# CCG2 register map
File version: 1.0
CPU: CM0 r1p0, little endian, no MPU, no FPU, 2 interrupt priority bits
Registers are 32-bit, read-write, reset 0x0 unless marked. A register's access mark holds for its fields unless they carry their own. Offsets are from the block's base; [hi:lo] are bit positions; {n}, {i} and the like mark numbered series; 'fields as' and 'values as' point back to an identical list.

## USBPD (part 2 of 2)
Base 0x40080000
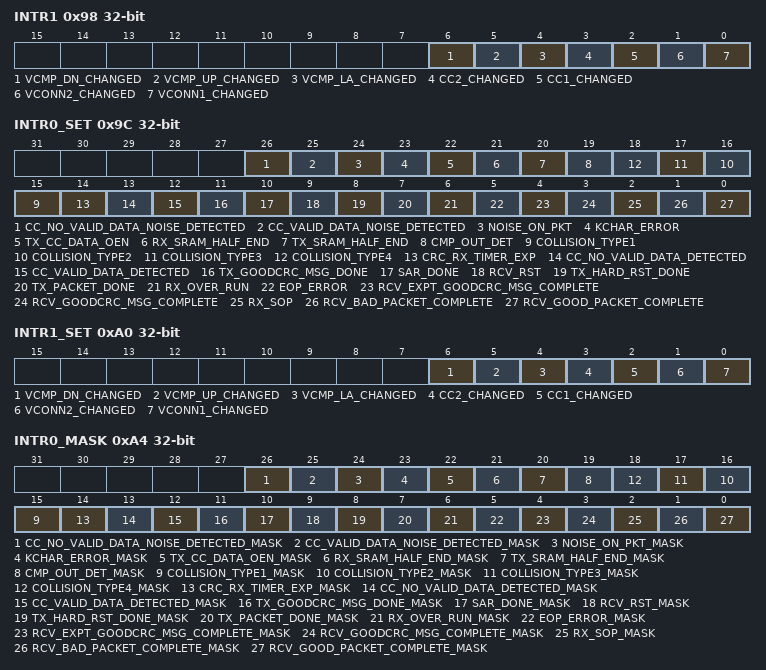
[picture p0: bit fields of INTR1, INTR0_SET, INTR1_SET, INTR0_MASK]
0x98 INTR1 — INTR1 Cause The configurations for using the comparators: DFP waiting for attach: vcmp_up connected to CC1: HI = no connect, LO = attach vcmp_dn connected to CC2: HI = no connect, LO = attach DFP after attach: vcmup_up at detach threshold: HI = detach, LO = attach vcmp_dn at Rd/Ra threshold: HI = Rd connected, LO = Ra connected vcmp_la at CC line activity threshold: HI = no activity, LO/Toggling = activity UFP (with VBUS present): vcmup_up at Default/1.5A threshold: HI = Default, LO = 1.5A vcmp_dn at 1.5A/3.0A threshold: HI = 1.5A, LO = 3.0A vcmp_la at CC line activity threshold: HI = no activity, LO/Toggling = activity For detecting the difference between Rd/Ra, firmware will have to check the �DFP after attach� state above to determine it.
  [6] VCMP_DN_CHANGED write-1-clears — VCMP_DN changed (wakeup interrupt from deepsleep) Check the STATUS.VCMP_DN_STATUS value
  [5] VCMP_UP_CHANGED write-1-clears — VCMP_UP changed (wakeup interrupt from deepsleep) Check the STATUS.VCMP_UP_STATUS value
  [4] VCMP_LA_CHANGED write-1-clears — VCMP_LA changed (wakeup interrupt from deepsleep) Check the STATUS.VCMP_LA_STATUS value
  [3] CC2_CHANGED write-1-clears — CC2 changed (wakeup interrupt from deepsleep) Check the STATUS.CC2_STATUS value
  [2] CC1_CHANGED write-1-clears — CC1 changed (wakeup interrupt from deepsleep) Check the STATUS.CC1_STATUS value
  [1] VCONN2_CHANGED write-1-clears — This interrupt can be either vconn2_changed or cmp_out Depending on the selection defined in DEBUG_CC_0.VCONN2_CMP_OUT_SEL VCONN2 changed/CMP_OUT (wakeup interrupt from deepsleep) Check the STATUS.VCONN2_STATUS value
  [0] VCONN1_CHANGED write-1-clears — VCONN1 changed (wakeup interrupt from deepsleep) Check the STATUS.VCONN1_STATUS value
0x9C INTR0_SET
  [26] CC_NO_VALID_DATA_NOISE_DETECTED write-1-sets — Write with '1' to set corresponding bit in interrupt request register.
  [25] CC_VALID_DATA_NOISE_DETECTED write-1-sets — Write with '1' to set corresponding bit in interrupt request register.
  [24] NOISE_ON_PKT write-1-sets — Write with '1' to set corresponding bit in interrupt request register.
  [23] KCHAR_ERROR write-1-sets — Write with '1' to set corresponding bit in interrupt request register.
  [22] TX_CC_DATA_OEN write-1-sets — Write with '1' to set corresponding bit in interrupt request register.
  [21] RX_SRAM_HALF_END write-1-sets — Write with '1' to set corresponding bit in interrupt request register.
  [20] TX_SRAM_HALF_END write-1-sets — Write with '1' to set corresponding bit in interrupt request register.
  [19] CMP_OUT_DET write-1-sets — Write with '1' to set corresponding bit in interrupt request register.
  [n+14] COLLISION_TYPE{n} write-1-sets (n=1..4) — Write with '1' to set corresponding bit in interrupt request register.
  [14] CRC_RX_TIMER_EXP write-1-sets — Write with '1' to set corresponding bit in interrupt request register.
  [13] CC_NO_VALID_DATA_DETECTED write-1-sets — Write with '1' to set corresponding bit in interrupt request register.
  [12] CC_VALID_DATA_DETECTED write-1-sets — Write with '1' to set corresponding bit in interrupt request register.
  [11] TX_GOODCRC_MSG_DONE write-1-sets — Write with '1' to set corresponding bit in interrupt request register.
  [10] SAR_DONE write-1-sets — Write with '1' to set corresponding bit in interrupt request register.
  [9] RCV_RST write-1-sets — Write with '1' to set corresponding bit in interrupt request register.
  [8] TX_HARD_RST_DONE write-1-sets — Write with '1' to set corresponding bit in interrupt request register.
  [7] TX_PACKET_DONE write-1-sets — Write with '1' to set corresponding bit in interrupt request register.
  [6] RX_OVER_RUN write-1-sets — Write with '1' to set corresponding bit in interrupt request register.
  [5] EOP_ERROR write-1-sets — Write with '1' to set corresponding bit in interrupt request register.
  [4] RCV_EXPT_GOODCRC_MSG_COMPLETE write-1-sets — Write with '1' to set corresponding bit in interrupt request register.
  [3] RCV_GOODCRC_MSG_COMPLETE write-1-sets — Write with '1' to set corresponding bit in interrupt request register.
  [2] RX_SOP write-1-sets — Write with '1' to set corresponding bit in interrupt request register.
  [1] RCV_BAD_PACKET_COMPLETE write-1-sets — Write with '1' to set corresponding bit in interrupt request register.
  [0] RCV_GOOD_PACKET_COMPLETE write-1-sets — Write with '1' to set corresponding bit in interrupt request register.
0xA0 INTR1_SET
  [6] VCMP_DN_CHANGED write-1-sets — Write with '1' to set corresponding bit in interrupt request register.
  [5] VCMP_UP_CHANGED write-1-sets — Write with '1' to set corresponding bit in interrupt request register.
  [4] VCMP_LA_CHANGED write-1-sets — Write with '1' to set corresponding bit in interrupt request register.
  [3] CC2_CHANGED write-1-sets — Write with '1' to set corresponding bit in interrupt request register.
  [2] CC1_CHANGED write-1-sets — Write with '1' to set corresponding bit in interrupt request register.
  [1] VCONN2_CHANGED write-1-sets — Write with '1' to set corresponding bit in interrupt request register.
  [0] VCONN1_CHANGED write-1-sets — Write with '1' to set corresponding bit in interrupt request register.
0xA4 INTR0_MASK
  [26] CC_NO_VALID_DATA_NOISE_DETECTED_MASK — Mask bit for corresponding bit in interrupt request register.
  [25] CC_VALID_DATA_NOISE_DETECTED_MASK — Mask bit for corresponding bit in interrupt request register.
  [24] NOISE_ON_PKT_MASK — Mask bit for corresponding bit in interrupt request register.
  [23] KCHAR_ERROR_MASK — Mask bit for corresponding bit in interrupt request register.
  [22] TX_CC_DATA_OEN_MASK — Mask bit for corresponding bit in interrupt request register.
  [21] RX_SRAM_HALF_END_MASK — Mask bit for corresponding bit in interrupt request register.
  [20] TX_SRAM_HALF_END_MASK — Mask bit for corresponding bit in interrupt request register.
  [19] CMP_OUT_DET_MASK — Mask bit for corresponding bit in interrupt request register.
  [n+14] COLLISION_TYPE{n}_MASK (n=1..4) — Mask bit for corresponding bit in interrupt request register.
  [14] CRC_RX_TIMER_EXP_MASK — Mask bit for corresponding bit in interrupt request register.
  [13] CC_NO_VALID_DATA_DETECTED_MASK — Mask bit for corresponding bit in interrupt request register.
  [12] CC_VALID_DATA_DETECTED_MASK — Mask bit for corresponding bit in interrupt request register.
  [11] TX_GOODCRC_MSG_DONE_MASK — Mask bit for corresponding bit in interrupt request register.
  [10] SAR_DONE_MASK — Mask bit for corresponding bit in interrupt request register.
  [9] RCV_RST_MASK — Mask bit for corresponding bit in interrupt request register.
  [8] TX_HARD_RST_DONE_MASK — Mask bit for corresponding bit in interrupt request register.
  [7] TX_PACKET_DONE_MASK — Mask bit for corresponding bit in interrupt request register.
  [6] RX_OVER_RUN_MASK — Mask bit for corresponding bit in interrupt request register.
  [5] EOP_ERROR_MASK — Mask bit for corresponding bit in interrupt request register.
  [4] RCV_EXPT_GOODCRC_MSG_COMPLETE_MASK — Mask bit for corresponding bit in interrupt request register.
  [3] RCV_GOODCRC_MSG_COMPLETE_MASK — Mask bit for corresponding bit in interrupt request register.
  [2] RX_SOP_MASK — Mask bit for corresponding bit in interrupt request register.
  [1] RCV_BAD_PACKET_COMPLETE_MASK — Mask bit for corresponding bit in interrupt request register.
  [0] RCV_GOOD_PACKET_COMPLETE_MASK — Mask bit for corresponding bit in interrupt request register.
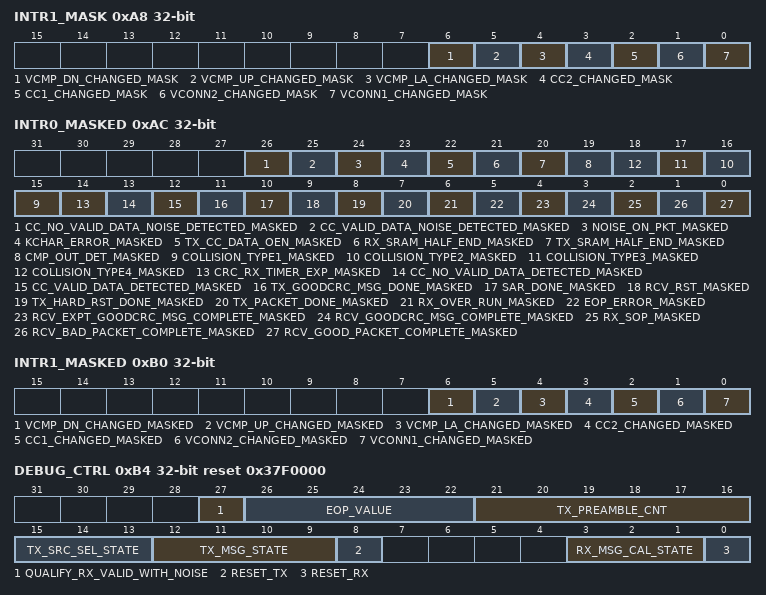
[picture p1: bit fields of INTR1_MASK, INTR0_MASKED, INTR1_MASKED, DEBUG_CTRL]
0xA8 INTR1_MASK
  [6] VCMP_DN_CHANGED_MASK — Mask bit for corresponding bit in interrupt request register.
  [5] VCMP_UP_CHANGED_MASK — Mask bit for corresponding bit in interrupt request register.
  [4] VCMP_LA_CHANGED_MASK — Mask bit for corresponding bit in interrupt request register.
  [3] CC2_CHANGED_MASK — Mask bit for corresponding bit in interrupt request register.
  [2] CC1_CHANGED_MASK — Mask bit for corresponding bit in interrupt request register.
  [1] VCONN2_CHANGED_MASK — Mask bit for corresponding bit in interrupt request register.
  [0] VCONN1_CHANGED_MASK — Mask bit for corresponding bit in interrupt request register.
0xAC INTR0_MASKED
  [26] CC_NO_VALID_DATA_NOISE_DETECTED_MASKED ro — Logical and of corresponding request and mask bits.
  [25] CC_VALID_DATA_NOISE_DETECTED_MASKED ro — Logical and of corresponding request and mask bits.
  [24] NOISE_ON_PKT_MASKED ro — Logical and of corresponding request and mask bits.
  [23] KCHAR_ERROR_MASKED ro — Logical and of corresponding request and mask bits.
  [22] TX_CC_DATA_OEN_MASKED ro — Logical and of corresponding request and mask bits.
  [21] RX_SRAM_HALF_END_MASKED ro — Logical and of corresponding request and mask bits.
  [20] TX_SRAM_HALF_END_MASKED ro — Logical and of corresponding request and mask bits.
  [19] CMP_OUT_DET_MASKED ro — Logical and of corresponding request and mask bits.
  [n+14] COLLISION_TYPE{n}_MASKED ro (n=1..4) — Logical and of corresponding request and mask bits.
  [14] CRC_RX_TIMER_EXP_MASKED ro — Logical and of corresponding request and mask bits.
  [13] CC_NO_VALID_DATA_DETECTED_MASKED ro — Logical and of corresponding request and mask bits.
  [12] CC_VALID_DATA_DETECTED_MASKED ro — Logical and of corresponding request and mask bits.
  [11] TX_GOODCRC_MSG_DONE_MASKED ro — Logical and of corresponding request and mask bits.
  [10] SAR_DONE_MASKED ro — Logical and of corresponding request and mask bits.
  [9] RCV_RST_MASKED ro — Logical and of corresponding request and mask bits.
  [8] TX_HARD_RST_DONE_MASKED ro — Logical and of corresponding request and mask bits.
  [7] TX_PACKET_DONE_MASKED ro — Logical and of corresponding request and mask bits.
  [6] RX_OVER_RUN_MASKED ro — Logical and of corresponding request and mask bits.
  [5] EOP_ERROR_MASKED ro — Logical and of corresponding request and mask bits.
  [4] RCV_EXPT_GOODCRC_MSG_COMPLETE_MASKED ro — Logical and of corresponding request and mask bits.
  [3] RCV_GOODCRC_MSG_COMPLETE_MASKED ro — Logical and of corresponding request and mask bits.
  [2] RX_SOP_MASKED ro — Logical and of corresponding request and mask bits.
  [1] RCV_BAD_PACKET_COMPLETE_MASKED ro — Logical and of corresponding request and mask bits.
  [0] RCV_GOOD_PACKET_COMPLETE_MASKED ro — Logical and of corresponding request and mask bits.
0xB0 INTR1_MASKED
  [6] VCMP_DN_CHANGED_MASKED ro — Logical and of corresponding request and mask bits.
  [5] VCMP_UP_CHANGED_MASKED ro — Logical and of corresponding request and mask bits.
  [4] VCMP_LA_CHANGED_MASKED ro — Logical and of corresponding request and mask bits.
  [3] CC2_CHANGED_MASKED ro — Logical and of corresponding request and mask bits.
  [2] CC1_CHANGED_MASKED ro — Logical and of corresponding request and mask bits.
  [1] VCONN2_CHANGED_MASKED ro — Logical and of corresponding request and mask bits.
  [0] VCONN1_CHANGED_MASKED ro — Logical and of corresponding request and mask bits.
0xB4 DEBUG_CTRL reset 0x37F0000 — Debug Control Register
  [27] QUALIFY_RX_VALID_WITH_NOISE — This bit is used to qualify the cc_rx_valid signal from cc module with the noise_detected for collision logic. 0: Don't qualify cc_rx_valid with noise_detected 1: Qualify cc_rx_valid with noise_detected
  [26:22] EOP_VALUE — EOP value for Both RX and TX
  [21:16] TX_PREAMBLE_CNT — Number of TX preambles+1 (bit transitions)
  [15:13] TX_SRC_SEL_STATE ro — TX SRC Select state machine
    0=IDLE_SEL; 1=CAL_SEL; 2=SYN_SEL; 3=KCHAR_SEL; 4=EOP_SEL; 5=RST_SEL
  [12:9] TX_MSG_STATE ro — Transmit state machine
    0=MSG_IDLE; 1=MSG_CAL; 2=MSG_SYN; 3=MSG_HDR; 4=MSG_DOBJ; 5=MSG_CRC; 6=MSG_EOP; 7=MSG_RST; 8=MSG_BIDLE
  [8] RESET_TX — This register are for debugging purposes 0: Transmit path is not at reset. 1: Reset the logic on the transmit path except the Hard-IP. FW should check STATUS.TX_BUSY to make sure it is zero before setting this bit.
  [3:1] RX_MSG_CAL_STATE ro — Message Cal State
    0=MSGSM_IDLE; 1=MSGSM_PRE_HDR; 2=MSGSM_HDR; 3=MSGSM_DATA; 4=MSGSM_CRC; 5=MSGSM_EOP; 6=MSGSM_STAT
  [0] RESET_RX — This register are for debugging purposes. 0: Receive path is not at reset. 1: Reset the logic on the receive path except the Hard-IP. FW should check STATUS.RX_BUSY to make sure it is zero before setting this bit.
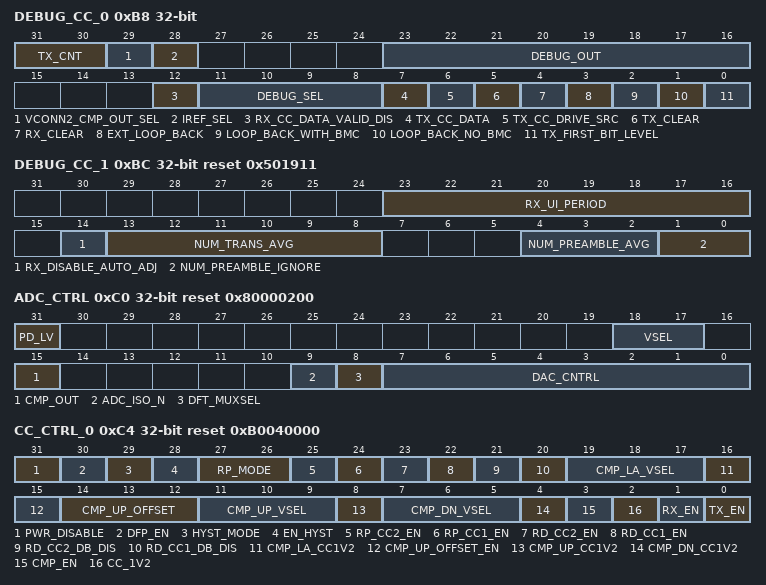
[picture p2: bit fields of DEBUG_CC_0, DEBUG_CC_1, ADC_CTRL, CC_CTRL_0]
0xB8 DEBUG_CC_0 — C-Connector Debug control register 0
  [31:30] TX_CNT — Used only for FPGA 0: Disabled Other values: BMC encoder in m0s8usbpd_cc_tx module uses clk_tx and clk_tx_half to transmit data at 300 KHz and clock transitions at 600 KHz. This scheme provides a 50% duty cycle at all time. However receivers are required to tolerate duty cycles of 35% to 65%. To help with debugging of the receiver logic, the duty cycle of transmit data can become variable. This feature is achieved by adding mmio_cc_tx_cnt<7:0> register
  [29] VCONN2_CMP_OUT_SEL — Selection bit for source of wakeup between vconn2_changed and cmp_out. 0: vconn2_changed is the source 1: cmp_out is the source
  [28] IREF_SEL — Selection bit for deepsleep vs. active current reference for Rp pull-up termination 0 - Select deepsleep current reference 1 - Select active current reference
  [23:16] DEBUG_OUT ro — Debug output register. Its inputs are selected by CC_DEBUG_SEL
  [12] RX_CC_DATA_VALID_DIS — 0: RX_CC_DATA_VALID signal is not disabled. 1: RX_CC_DATA_VALID signal is disabled.
  [11:8] DEBUG_SEL — Selects the inputs to CC_DEBUG_OUT. Used for debug. 0. RX clk_cnt_q 1. RX cnt_max_q 2. RX cnt_min_q 3. Not defined yet. 4. RX {rx_state_q, cc_rx_data_del_q, one_detect_q} 5. RX {4'h0, cq_2, cq_3, cq_4, cq_5} 6. RX {2'h0, cc_rx_data, cc_rx_bit, cc_rx_valid, cc_rx_data_pin, cc_tx_data_pin, cc_data_pin_oe} 7. Not defined yet. 8. Not defined yet. 9. TX {2'h0, tx_state_q, new_data_q} 10. TX {2'h0, cq_0, cq_3, cc_tx_data_lat_q, cc_tx_eof_lat_q, cc_tx_data_valid_lat_q, cc_new_data_lat_q} 11. TX {3'h0, cc_tx_data_pin, cc_data_pin_oe, cc_tx_data, cc_tx_eof, cc_tx_data_valid} 12-15 not defined yet.
  [7] TX_CC_DATA — FW can use this bit to dirve the CC data line when the TX_CC_DRIVE_SRC=1 and CC_DPSLP_REF_CTRL.TX_EN=1 When TX_CC_DRIVE_SRC is set to one: - TX_EN port of the s8usbpd_cc_top is controlled by CC_DPSLP_REF_CTRL.TX_EN - TX_DATA port of s8usbpd_cc_top Hard IP is controlled by TX_CC_DATA
  [6] TX_CC_DRIVE_SRC — This will selects either the m0s8usbpd_cc_tx or FW to control the TX_EN/TX_DATA ports of the s8usbpd_cc_top Hard IP. 0: Hardware (m0s8usbpd_cc_tx) controls the TX_EN/TX_DATA ports of the s8usbpd_cc_top Hard IP. 1: This option is for Testing/Char. FW controls the TX_EN/TX_DATA ports of the s8usbpd_cc_top Hard IP.
  [5] TX_CLEAR — When set to one, clears the TX state machines and counters. It has to be set back to zero for normal operations.
  [4] RX_CLEAR — When set to one, clears the BMC decoder RX state machines and counters. It has to be set back to zero for normal operations. RX_RESET is not required to be set
  [3] EXT_LOOP_BACK — When set, enables rx module to decode cc_rx line all the time. (Including during transmission).
  [2] LOOP_BACK_WITH_BMC — Loobback after data encdoing. When set, the BMC encoded tx output will loop back into cc_rx module.
  [1] LOOP_BACK_NO_BMC — When set enables TX to RX loopback before CC encoding/Decoding data.
  [0] TX_FIRST_BIT_LEVEL — FW can only use this bit when the DEBUG_CC_0.TX_CC_DRIVE_SRC is set to "1". 0: Disables the Transceiver to transmit data 1: Enables the Transceiver to transmit data
0xBC DEBUG_CC_1 reset 0x501911 — C-Connector Debug control register 1
  [23:16] RX_UI_PERIOD — When RX_DISABLE_AUTO_ADJ is set, this register value will define RX UI period.
  [14] RX_DISABLE_AUTO_ADJ — 0: Automatic bit rate calculation by HW 1: Disables the RX-CC automatic bit rate detection and the RX_UI_PRERIOD register is used for RX UI period.
  [13:8] NUM_TRANS_AVG — Number of transitions required to complete averaging in the receiver. This register will need to be updated any time values of NUM_PREAMBLE_AVG is changed. The values programmed into this register comes from the following table: NUM_PREAMBLE_AVG = 000 : Use 0x19 NUM_PREAMBLE_AVG = 001 : Use 0x19 NUM_PREAMBLE_AVG = 010 : Use 0x7 NUM_PREAMBLE_AVG = 011 : Use 0xd NUM_PREAMBLE_AVG = 100 : Use 0x19 NUM_PREAMBLE_AVG = 101 : Use 0x31
  [4:2] NUM_PREAMBLE_AVG — Number of preamble bits to be used in the RX for averaging CDR frequency. Any time the value of these bits are changed, the values of NUM_TRANS_AVG will need to be updated.
    0=FOUR_PREAM_AVG0; 1=FOUR_PREAM_AVG1; 2=FOUR_PREAM_AVG2; 3=EIGHT_PREAM_AVG; 4=SIXTEEN_PREAM_AVG; 5=THIRTY_TWO_PREAM_AVG; 6=RESERVED6_PREAM_AVG; 7=RESERVED7_PREAM_AVG
  [1:0] NUM_PREAMBLE_IGNORE — Number of preamble bits to ignore at the beginning of the RX packet.
0xC0 ADC_CTRL reset 0x80000200 — S8USBPD DAC Control Register
  [31] PD_LV — ADC Power down control, active high.
  [18:17] VSEL — Input Voltage select
    0=ANA_IN1_AMUX_A; 1=ANA_IN2_AMUX_A; 2=BAND_GAP; 3=BJT
  [15] CMP_OUT ro — Comparator Output. If voltage on ID pin is less than DAC voltage, then cmp_out is HIGH.
  [9] ADC_ISO_N — This is for when high voltage supply for a port is not present. This bit should be set when the high voltage is present, in order to ensure that the outputs are set to know values. 0: All outputs are isolated to a known value 1: Normal operation
  [8] DFT_MUXSEL — ADC DFT Control: 0: Normal operation 1: DAC output voltage
  [7:0] DAC_CNTRL — Control bits for 8-bit DAC. DAC_CNTRL register is used only if CPU wants to implement the SAR algorithm in FW.
0xC4 CC_CTRL_0 reset 0xB0040000 — S8USBPD C-connector Control Register 0
  [31] PWR_DISABLE — Disables all active circuitry and DC paths DS_ATTACH_DET_EN is still active
  [30] DFP_EN — Controls the reference voltage generator for DFP vs. UFP/Cable operation 0: UFP/Cable - voltage reference is 2.4V 1: DFP - voltage reference is 2.6V" This register is a user configuration that must be set.
  [29] HYST_MODE — Selects the amount of line activity comparator hysteresis 0: 50mV hystersis 1: 100mV hysteresis"
  [28] EN_HYST — Enables the hysteresis mode for the line activity comparator
  [27:26] RP_MODE — Selects the Pull-up Termination current value 0, 2 - 80uA (Default current broadcast) 1 - 180uA (1.5A current broadcast) 3 - 330uA (3.0A current broadcast)
    0=PU0_80_UA; 1=PU1_1p5_A; 2=PU2_80_UA; 3=PU3_3A
  [25] RP_CC2_EN — 0: Disable CC2 Pull-up Termination (Rp) 1: Enable CC2 Pull-up Termination
  [24] RP_CC1_EN — 0: Disable CC1 Pull-up Termination (Rp) 1: Enable CC1 Pull-up Termination
  [23] RD_CC2_EN — 0: Disable CC2 Trimmed Rd Termination 1: Enable CC2 Trimmed Rd Termination
  [22] RD_CC1_EN — 0: Disable CC1 Trimmed Rd Termination 1: Enable CC1 Trimmed Rd Termination
  [21] RD_CC2_DB_DIS — Disable Dead Battery Rd termination on CC2
  [20] RD_CC1_DB_DIS — Disable Dead Battery Rd termination on CC1
  [19:17] CMP_LA_VSEL — Selects the voltage threshold for cmp_la comparator
    0=SEL_0_2_VOL; 1=SEL_0_4_VOL; 2=SEL_0_55_VOL; 3=SEL_0_655_VOL; 4=SEL_0_8_VOL; 5=SEL_1_235_VOL; 6=SEL_1_575_VOL; 7=SEL_2_6_VOL
  [16] CMP_LA_CC1V2 — Connects cmp_la comparator to CC1/CC2 0 - CC1 1 - CC2
  [15] CMP_UP_OFFSET_EN — Enables the offset generator for the cmp_up comparator 0 - no offset 1 - offset enabled, see CMP_UP_OFFSET register for value
  [14:12] CMP_UP_OFFSET — Selects the cmp_up comparator offset:
    0=SEL_MINUS_50_MV; 1=SEL_MINUS_100_MV; 2=SEL_MINUS_150_MV; 3=SEL_MINUS_200_MV; 4=SEL_PLUS_50_MV; 5=SEL_PLUS_100_MV; 6=SEL_PLUS_150_MV; 7=SEL_PLUS_200_MV
  [11:9] CMP_UP_VSEL — Selects the voltage threshold for cmp_up comparator
    0=SEL_0_2_VOL; 1=SEL_0_4_VOL; 2=SEL_0_3_VOL; 3=SEL_0_655_VOL; 4=SEL_0_8_VOL; 5=SEL_1_235_VOL; 6=SEL_1_575_VOL; 7=SEL_2_6_VOL
  [8] CMP_UP_CC1V2 — Connects cmp_up comparator to CC1/CC2 0 - CC1 1 - CC2
  [7:5] CMP_DN_VSEL — Selects the voltage threshold for cmp_dn comparator
    values as CMP_LA_VSEL
  [4] CMP_DN_CC1V2 — Connects cmp_dn comparator to CC1/CC2 0 - CC1 1 - CC2
  [3] CMP_EN — CC line voltage Comparator enable
  [2] CC_1V2 — Firmware detects cable attach and specifies whether CC1 or CC2 is connected to the CC-line of the cable. 0 - CC1 1 - CC2
  [1] RX_EN — Enables the Transceiver to receive data, Active High This bit should be set after CC Line active interrupt (wakeup) in DeepSleep. FW should set this bit at init and not change after across deep sleep and wake.
  [0] TX_EN — FW can only use this bit when the DEBUG_CC_0.TX_CC_DRIVE_SRC is set to "1". 0: Disables the Transceiver to transmit data 1: Enables the Transceiver to transmit data
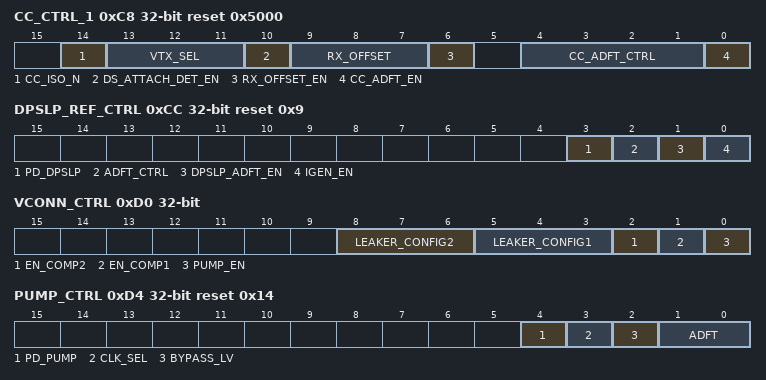
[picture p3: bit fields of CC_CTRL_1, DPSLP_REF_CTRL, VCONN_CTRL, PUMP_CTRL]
0xC8 CC_CTRL_1 reset 0x5000 — S8USBPD C-connector Control Register 1
  [14] CC_ISO_N — 0: All outputs are isolated to a known value 1: Normal operation
  [13:11] VTX_SEL — Transmit voltage select
    0=SEL_0_93_V; 1=SEL_1_03_V; 2=SEL_1_125_V; 3=SEL_1_225_V; 4=SEL_1_33_V; 5=SEL_1_43_V; 6=SEL_1_53_V; 7=SEL_1_63_V
  [10] DS_ATTACH_DET_EN — Enables the deepsleep attach detect pull-up resistor Set HI for a DFP waiting for attach
  [9:7] RX_OFFSET — Selects the RX comparator offset:
    values as CC_CTRL_0.CMP_UP_OFFSET
  [6] RX_OFFSET_EN — Enables the offset generator for the RX comparator 0 - no offset 1 - offset enabled, see RX_OFFSET register for value
  [4:1] CC_ADFT_CTRL — Selects ADFT connection See s8usbpd BROS for decoding details
  [0] CC_ADFT_EN — Enables ADFT Mode
0xCC DPSLP_REF_CTRL reset 0x9 — S8USBPD DeepSleep-Reference Control Register
  [3] PD_DPSLP — Block enable input 1 - All analog and DC paths cut off, outputs forced to known value This completely disables the CC Transceiver/Detect block. 0 - Normal functionality
  [2] ADFT_CTRL — Controls the Deep Sleep reference ADFT mode 0: ganged 7 iref current sources 1: vrefdpslp voltage reference
  [1] DPSLP_ADFT_EN — Setting this bit will enable the deepsleep reference generator ADFT mode.
  [0] IGEN_EN — Setting this bit will enable the deepsleep current reference outputs.
0xD0 VCONN_CTRL — S8USBPD VCONN control Register
  [8:6] LEAKER_CONFIG2 — VCONN2 leaker control
    0=LEAKER_DIS; 1=SEL_200_UA; 2=SEL_0_1_UF; 3=SEL_0_5_UF; 4=SEL_1_UF; 5=SEL_2_UF; 6=SEL_5_UF; 7=SEL_10_UF
  [5:3] LEAKER_CONFIG1 — VCONN1 leaker control
    values as LEAKER_CONFIG2
  [2] EN_COMP2 — Enable VCONN2 comparator
  [1] EN_COMP1 — Enable VCONN1 comparator
  [0] PUMP_EN — Negative Charge Pump enable signal 0 - Pump disabled: Ra termination is present on both VCONN1 and VCONN2 1 - Pump enabled: Ra termination is cutoff on VCONN1 only if the EN_COMP1 is set Ra termination is cutoff on VCONN2 only if the EN_COMP2 is set
0xD4 PUMP_CTRL reset 0x14 — S8USBPD PUMP control Register
  [4] PD_PUMP — Pump powerdown signal 0: Pump enabled 1: Pump disabled, all current paths cutoff
  [3] CLK_SEL — External clock select 0: Internal oscillator used for charge pump 1: External clock used for charge pump
  [2] BYPASS_LV — Bypasses the pumped output. Pump output is connected to VDDD. 0: Charge pump output 1: Pump output shorted to VDDD
  [1:0] ADFT — ADFT control
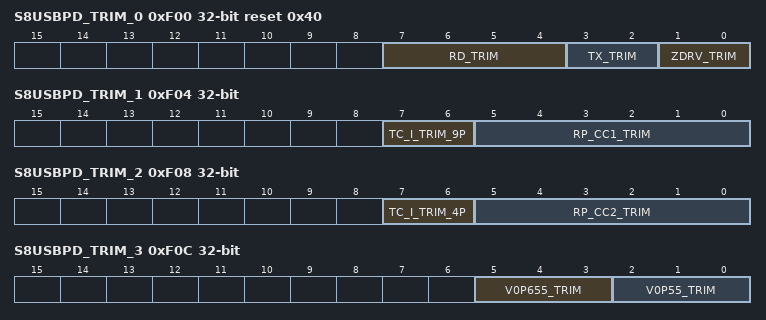
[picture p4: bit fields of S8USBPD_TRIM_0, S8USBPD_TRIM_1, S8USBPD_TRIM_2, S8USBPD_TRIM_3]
0xF00 S8USBPD_TRIM_0 reset 0x40 — S8USBPD Trim Register0 . Production trims stored in flash
  [7:4] RD_TRIM — Trim bits for Rd pull-down resistor
  [3:2] TX_TRIM — Trim bits for TX Driver rise/fall slew rate
  [1:0] ZDRV_TRIM — Trim bits for Driver termination impedance
0xF04 S8USBPD_TRIM_1 — S8USBPD Trim Register1 . Production trims stored in flash
  [7:6] TC_I_TRIM_9P — DeepSleep 2.4uA current reference temperature coefficient trim bit
  [5:0] RP_CC1_TRIM — Trim bits for CC1 Pull-up current source Firmware may need to read SFlash from location TBD and set this value for each Rp value (RP_MODE)
0xF08 S8USBPD_TRIM_2 — S8USBPD Trim Register2 . Production trims stored in flash
  [7:6] TC_I_TRIM_4P — DeepSleep 2.4uA current reference temperature coefficient trim bit
  [5:0] RP_CC2_TRIM — [5:0]: Trim bits for CC2 Pull-up current source Firmware may need to read SFlash from location TBD and set this value for each Rp value (RP_MODE) [7:6]: Not Used. Spare trim bits
0xF0C S8USBPD_TRIM_3 — S8USBPD C-connector Trim Register3. Production trims stored in flash
  [5:3] V0P655_TRIM — Trim bits for 0.655V comparator reference
  [2:0] V0P55_TRIM — Trim bits for 0.55V comparator reference
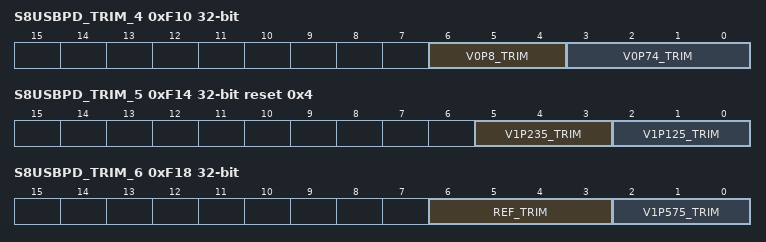
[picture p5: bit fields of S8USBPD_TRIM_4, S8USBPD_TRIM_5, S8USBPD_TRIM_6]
0xF10 S8USBPD_TRIM_4 — S8USBPD C-connector Trim Register4. Production trims stored in flash
  [6:4] V0P8_TRIM — Trim bits for 0.8V comparator reference
  [3:0] V0P74_TRIM — Trim bits for 0.74V comparator reference
0xF14 S8USBPD_TRIM_5 reset 0x4 — S8USBPD C-connector Trim Register5. Production trims stored in flash
  [5:3] V1P235_TRIM — Trim bits for 1.235V comparator reference
  [2:0] V1P125_TRIM — Trim bits for 1.125V comparator reference
0xF18 S8USBPD_TRIM_6 — S8USBPD C-connector Trim Register6. Production trims stored in flash
  [6:3] REF_TRIM — Beta multiplier reference trim bits. Refer to GPM-541 for trim settings.
  [2:0] V1P575_TRIM — Trim bits for 1.575V comparator reference
0xF1C S8USBPD_TRIM_7 reset 0xF1 — S8USBPD C-connector Trim Register7. Production trims stored in flash
  [7:0] I_TRIM — DeepSleep 2.4uA current reference trim bit. Refer to s8usbpd BROS for bit settings.
